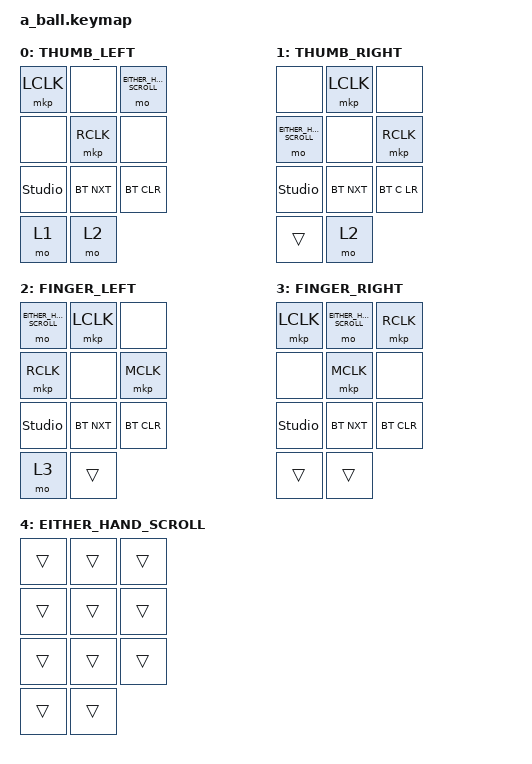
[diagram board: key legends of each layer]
#include <behaviors.dtsi>
#include <dt-bindings/zmk/keys.h>
#include <dt-bindings/zmk/bt.h>
//#include <dt-bindings/zmk/mouse.h>

#include <dt-bindings/zmk/outputs.h>
#include <dt-bindings/zmk/mouse.h>
#include <dt-bindings/zmk/ext_power.h>
//#include <behaviors/mouse_keys.dtsi>
//#include <input/processors.dtsi>


#define THUMB_LEFT  0
#define THUMB_RIGHT 1
#define FINGER_LEFT 2
#define FINGER_RIGHT 3 
#define EITHER_HAND_SCROLL 4

// Mouse speed increased
#define ZMK_POINTING_DEFAULT_MOVE_VAL 1000  // default: 600
#define ZMK_POINTING_DEFAULT_SCRL_VAL 15    // default: 10
//#include <dt-bindings/zmk/pointing.h>

// #define LEFT_HAND     	0
// #define RIGHT_HAND     	1
// #define EITHER_HAND_SCROLL	2

/ {
    keymap {
        compatible = "zmk,keymap";

//        map = <
//		                 /* Ball */
//	         	RC(0,3)              RC(0,0) 
//		 RC(0,4)                            RC(0,1)
//   		 RC(0,5) 	                    RC(0,2) 
//                  /* Buttons on top of the middle deck */
//  		       /* Unlock  BTSelect BTReset */ 
//                          RC(0,6) RC(0,7)  RC(0,8)        
//               /* Slider switches on the bottom of the middle deck */
//		/* Handiness L/R   Orientation Thumb/Fingers  */
//                      RC(0,10)               RC(0,9)      
//        >;

// &mkp LCLK &mkp MCLK &mkp RCLK  &none

	// Layer 0
        THUMB_LEFT {
            bindings = <
			&mkp LCLK             	&none
		&mo EITHER_HAND_SCROLL               &none
		&mkp RCLK                            &none
	                       /* Buttons  */
		&studio_unlock  &bt BT_NXT   &bt BT_CLR
			&mo 1                 &mo 2
            >;
        };


	// Layer 1
        THUMB_RIGHT {
            bindings = <
     			&none         		&mkp LCLK             
	       &none  				     &mo EITHER_HAND_SCROLL        
	       &none  	 			     &mkp RCLK                     
	                       /* Buttons  */
		&studio_unlock  &bt BT_NXT   &bt BT_C LR
			&trans                  &mo 2
            >;
        };

	// Layer 2
        FINGER_LEFT {
            bindings = <
			&mo EITHER_HAND_SCROLL	&mkp LCLK             
		&none					&mkp RCLK
		&none					&mkp MCLK
	                       /* Buttons  */
		&studio_unlock  &bt BT_NXT   &bt BT_CLR
			&mo 3                 &trans
            >;
        };

	// Layer 3
        FINGER_RIGHT {
            bindings = <
			&mkp LCLK             &mo EITHER_HAND_SCROLL
		&mkp RCLK				&none	
		&mkp MCLK                               &none	
	                       /* Buttons  */
		&studio_unlock  &bt BT_NXT   &bt BT_CLR
			&trans                 &trans
            >;
        };


	// Scroll layers do nothing by themselves, it is completely transparent.
	// It is detected in trackball_listener telling to switch from the pointing movement to scrolling.
        EITHER_HAND_SCROLL {
            bindings = <
		&trans	&trans	&trans
		&trans	&trans	&trans
		&trans	&trans	&trans
	     	&trans	&trans	
            >;
        };


    };

};
